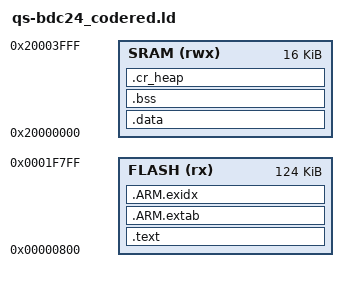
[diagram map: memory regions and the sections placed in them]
/******************************************************************************
 *
 * qs-bdc24_codered.ld - Code Red linker configuration file for qs-bdc24.
 *
 * Copyright (c) 2008-2012 Texas Instruments Incorporated.  All rights reserved.
 * Software License Agreement
 * 
 * Texas Instruments (TI) is supplying this software for use solely and
 * exclusively on TI's microcontroller products. The software is owned by
 * TI and/or its suppliers, and is protected under applicable copyright
 * laws. You may not combine this software with "viral" open-source
 * software in order to form a larger program.
 * 
 * THIS SOFTWARE IS PROVIDED "AS IS" AND WITH ALL FAULTS.
 * NO WARRANTIES, WHETHER EXPRESS, IMPLIED OR STATUTORY, INCLUDING, BUT
 * NOT LIMITED TO, IMPLIED WARRANTIES OF MERCHANTABILITY AND FITNESS FOR
 * A PARTICULAR PURPOSE APPLY TO THIS SOFTWARE. TI SHALL NOT, UNDER ANY
 * CIRCUMSTANCES, BE LIABLE FOR SPECIAL, INCIDENTAL, OR CONSEQUENTIAL
 * DAMAGES, FOR ANY REASON WHATSOEVER.
 * 
 * This is part of revision 8555 of the RDK-BDC24 Firmware Package.
 *
 *****************************************************************************/

MEMORY
{
    FLASH (rx) : ORIGIN = 0x00000800, LENGTH = 0x0001f000
    SRAM (rwx) : ORIGIN = 0x20000000, LENGTH = 0x00004000
}

SECTIONS
{
    _vRamTop = 0x20000000 + 0x00004000;
    .text :
    {
        KEEP(*(.isr_vector))
        *(.text*)
        *(.rodata*)
    } > FLASH

    /*
     * for exception handling/unwind - some Newlib functions (in common with
     * C++ and STDC++) use this.
     */

    .ARM.extab :
    {
        *(.ARM.extab* .gnu.linkonce.armextab.*)
    } > FLASH

    __exidx_start = .;
    .ARM.exidx :
    {
        *(.ARM.exidx* .gnu.linkonce.armexidx.*)
    } > FLASH
    __exidx_end = .;

    _etext = .;

    .data : AT (__exidx_end)
    {
        _data = .;
        *(vtable)
        *(.data*)
        _edata = .;
    } > SRAM

    /* zero initialized data */

    .bss :
    {
        _bss = .;
        *(.bss*)
        *(COMMON)
        _ebss = .;
    } > SRAM

    /* Where we put the heap with cr_clib */

    .cr_heap :
    {
        end = .;
        _pvHeapStart = .;
    } > SRAM

    /*
     * Note: (ref: M0000066)
     * Moving the stack down by 16 is to work around a GDB bug.
     * This space can be reclaimed for Production Builds.
     */

    _vStackTop = _vRamTop - 16;
}
